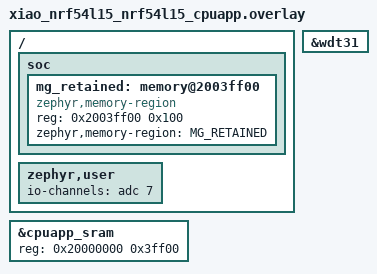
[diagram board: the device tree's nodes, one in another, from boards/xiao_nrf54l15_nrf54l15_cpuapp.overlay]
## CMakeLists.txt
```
# Copyright (c) Meta Platforms, Inc. and affiliates.
#
# Licensed under the Apache License, Version 2.0 (the "License");
# you may not use this file except in compliance with the License.
# You may obtain a copy of the License at
#
#     http://www.apache.org/licenses/LICENSE-2.0
#
# Unless required by applicable law or agreed to in writing, software
# distributed under the License is distributed on an "AS IS" BASIS,
# WITHOUT WARRANTIES OR CONDITIONS OF ANY KIND, either express or implied.
# See the License for the specific language governing permissions and
# limitations under the License.

cmake_minimum_required(VERSION 3.20.0)

# Before Zephyr's Kconfig runs: the version strings.
include(${CMAKE_CURRENT_SOURCE_DIR}/cmake/mg_version.cmake)

find_package(Zephyr REQUIRED HINTS $ENV{ZEPHYR_BASE})
project(muse_gadget_zephyr)

# The image id's build variant, guessed before Kconfig, against the effective
# configuration (cmake/mg_image_id.cmake): a mismatch fails the build.
mg_image_variant_check(${MG_IMAGE_VARIANT})

# The XIAO's flash map (mcuboot, slot0, slot1, storage) boots through MCUboot:
# without it the image would sit at slot0 with nothing at 0 to start it.
if(CONFIG_BOARD_XIAO_NRF54L15 AND NOT CONFIG_BOOTLOADER_MCUBOOT)
  message(FATAL_ERROR "Build the XIAO nRF54L15 with --sysbuild: it boots through MCUboot "
    "(sysbuild.conf). See AGENTS.md, Build.")
endif()

include(${CMAKE_CURRENT_SOURCE_DIR}/cmake/mg_common.cmake)

target_include_directories(app PRIVATE ${MG_PROTOCOLS} src)

target_sources(app PRIVATE
  src/main.c
  src/mg_core.c
  src/mg_clock.c
  src/mg_power.c
  src/mg_boot.c
  src/mg_health.c
  src/mg_settings.c
  src/mg_session.c
  src/mg_identity.c
  src/mg_json.c
  src/mg_psa.c
  src/mg_setup.c
  src/mg_setup_crypto.c
  src/mg_setup_store.c
  src/mg_token_proof.c
  src/mg_codec.c
  src/mg_audio.c
  src/mg_hpf.c
  src/mg_ble.c
  src/mg_connparam.c
  src/mg_throughput.c
  src/mg_led.c
  src/mg_led_pattern.c
  src/mg_button.c
)
# The TX path's ACL leg counts the controller's completed packets (mg_ble.c): the
# host's bt_conn_tx_notify(conn, false), once per Number of Completed Packets.
zephyr_link_libraries(-Wl,--wrap=bt_conn_tx_notify)
# A disconnect the host asks for on its own TX processor goes out from the
# system work queue (src/mg_bt_txfix.c: Zephyr v4.4.2's host would wait there
# for a command only that thread sends, then assert after 10 s).
if(CONFIG_BT_TX_PROCESSOR_THREAD AND CONFIG_BT_CONN)
  target_sources(app PRIVATE src/mg_bt_txfix.c)
  zephyr_link_libraries(-Wl,--wrap=bt_send -Wl,--wrap=bt_hci_disconnect)
endif()
target_sources_ifdef(CONFIG_MG_VM_SESSION app PRIVATE
  src/mg_envelope.c
  src/mg_vm_session.c
  src/mg_vm_link.c
  src/mg_vm_commands.c
  # Sealed credentials: the shared seal, vendored
  # unchanged, on this app's PSA Crypto.
  ../portable/mg_device_session/src/mg_session_seal.c
  src/mg_seal_crypto.c
)
if(CONFIG_MG_VM_SESSION)
  # After src: this app's own mg_token_proof.h comes first.
  target_include_directories(app PRIVATE
    ../portable/mg_device_session/include ../portable/mg_link_setup/include)
  # mgls_crypto.h's PSA types. MGSEAL_EXT_SHA stays 0 here: the seal's own
  # SHA-256 is smaller on this app than PSA's multipart hash, which nothing
  # else links (MGSEAL_EXT_SHA=1 measured +1,252 B of flash).
  target_compile_definitions(app PRIVATE MGLS_CRYPTO_PSA)
endif()
target_sources_ifdef(CONFIG_MG_AUDIO_QUEUE app PRIVATE src/mg_queue.c)
# A board's own app code (its board hooks, mg_app.h) lives beside the app in a
# directory with an app_ext.cmake; each one includes itself when its board
# builds.
file(GLOB mg_app_exts ${CMAKE_CURRENT_SOURCE_DIR}/*/app_ext.cmake)
foreach(ext ${mg_app_exts})
  include(${ext})
endforeach()
target_sources_ifdef(CONFIG_MG_BATTERY_ADC app PRIVATE src/mg_battery.c)
target_sources_ifdef(CONFIG_MG_SDK_TOKEN_SLOT app PRIVATE src/mg_token_slot.c)
if(CONFIG_MG_SDK_TOKEN_SLOT)
  # The updater finds the slot by its marker: exactly once in the image,
  # checked on zephyr.bin after every link.
  add_custom_target(mg_token_slot_check ALL
    COMMAND ${PYTHON_EXECUTABLE} ${CMAKE_CURRENT_SOURCE_DIR}/tools/check_token_slot.py
            ${ZEPHYR_BINARY_DIR}/${KERNEL_BIN_NAME}
    VERBATIM)
  add_dependencies(mg_token_slot_check zephyr_final)
endif()
if(NOT CONFIG_ARCH_POSIX)
  # Every Nordic UART word is classified and gated (tools/check_nus_words.py):
  # before the app compiles, so an unclassified word never builds.
  add_custom_target(mg_nus_words_check ALL
    COMMAND ${PYTHON_EXECUTABLE} ${CMAKE_CURRENT_SOURCE_DIR}/tools/check_nus_words.py
            ${CMAKE_CURRENT_SOURCE_DIR}/src/mg_nus.c ${CMAKE_CURRENT_SOURCE_DIR}/src/mg_nus_policy.h
    VERBATIM)
  add_dependencies(app mg_nus_words_check)
  # Every owner-content wireless read is listed and gated
  # (tools/check_owner_reads.py, src/mg_owner_reads.h).
  add_custom_target(mg_owner_reads_check ALL
    COMMAND ${PYTHON_EXECUTABLE} ${CMAKE_CURRENT_SOURCE_DIR}/tools/check_owner_reads.py
            ${CMAKE_CURRENT_SOURCE_DIR}/src
    VERBATIM)
  add_dependencies(app mg_owner_reads_check)
  # No log line formats a secret or a hex buffer (every line can reach the
  # Nordic UART mirror; tools/check_log_secrets.py), board code included:
  # every directory beside src/ with an app_ext.cmake.
  set(mg_app_ext_dirs)
  file(GLOB mg_app_ext_files ${CMAKE_CURRENT_SOURCE_DIR}/*/app_ext.cmake)
  foreach(mg_ext ${mg_app_ext_files})
    get_filename_component(mg_ext_dir ${mg_ext} DIRECTORY)
    list(APPEND mg_app_ext_dirs ${mg_ext_dir})
  endforeach()
  add_custom_target(mg_log_secrets_check ALL
    COMMAND ${PYTHON_EXECUTABLE} ${CMAKE_CURRENT_SOURCE_DIR}/tools/check_log_secrets.py
            ${CMAKE_CURRENT_SOURCE_DIR}/src ${mg_app_ext_dirs}
    VERBATIM)
  add_dependencies(app mg_log_secrets_check)
  # The malloc arena (all RAM no static data uses) holds both the device
  # session's block and SMP's, the BLE recovery tier: a build whose statics
  # leave too little fails here instead of an update failing in the field
  # (tools/check_arena.py).
  if(CONFIG_COMMON_LIBC_MALLOC_ARENA_SIZE EQUAL -1 AND CONFIG_MCUMGR)
    math(EXPR mg_ram_end "${CONFIG_SRAM_BASE_ADDRESS} + ${CONFIG_SRAM_SIZE} * 1024" OUTPUT_FORMAT HEXADECIMAL)
    add_custom_target(mg_arena_check ALL
      COMMAND ${PYTHON_EXECUTABLE} ${CMAKE_CURRENT_SOURCE_DIR}/tools/check_arena.py
              --nm ${CMAKE_NM} --elf ${ZEPHYR_BINARY_DIR}/${KERNEL_ELF_NAME}
              --ram-end ${mg_ram_end} --min-kb 48
      VERBATIM)
    add_dependencies(mg_arena_check zephyr_final)
  endif()
  # The mic's token-proof gate is linked, and a release image has no bench
  # path around it (tools/check_mic_gate.py): checked after every link. A
  # bench-mode image passes its own build's check (--bench-mode); what
  # refuses it as a release is its .bench marker and a separate
  # check_mic_gate.py --release run without --bench-mode (publish tooling).
  if(CONFIG_MG_AUTOMATION)
    set(mg_mic_release "")
  elseif(CONFIG_MG_BENCH_MODE)
    set(mg_mic_release --release --bench-mode)
  else()
    set(mg_mic_release "--release")
  endif()
  add_custom_target(mg_mic_gate_check ALL
    COMMAND ${PYTHON_EXECUTABLE} ${CMAKE_CURRENT_SOURCE_DIR}/tools/check_mic_gate.py
            --nm ${CMAKE_NM} --elf ${ZEPHYR_BINARY_DIR}/${KERNEL_ELF_NAME}
            --bin ${ZEPHYR_BINARY_DIR}/${KERNEL_BIN_NAME} ${mg_mic_release}
    VERBATIM)
  add_dependencies(mg_mic_gate_check zephyr_final)
endif()
target_sources_ifdef(CONFIG_MG_NUS app PRIVATE src/mg_nus.c)
if(CONFIG_MCUMGR_TRANSPORT_BT AND NOT CONFIG_MG_DFU AND NOT CONFIG_MG_SMP_GATE_BOARD)
  # mg_ota.c (or mg_smp_gate.c) holds the update writes' token-proof gate:
  # without one SMP over Bluetooth would take updates from anyone.
  message(FATAL_ERROR "CONFIG_MCUMGR_TRANSPORT_BT needs CONFIG_MG_DFU (the update gate) or "
                      "CONFIG_MG_SMP_GATE_BOARD; turn it off for a build without Bluetooth updates")
endif()
if(CONFIG_MG_SMP_GATE_BOARD)
  # Each request's source connection (src/mg_smp_req_gen.c): its first
  # fragment's, stamped where the transport hands the request over, read
  # while its handlers run; with reassembly a partly received request whose
  # connection is gone is dropped before the next write is collected.
  target_sources(app PRIVATE src/mg_smp_gate.c src/mg_smp_req_gen.c)
  zephyr_link_libraries(-Wl,--wrap=smp_rx_req -Wl,--wrap=smp_process_request_packet)
  if(CONFIG_MCUMGR_TRANSPORT_REASSEMBLY)
    target_include_directories(app PRIVATE ${ZEPHYR_BASE}/subsys/mgmt/mcumgr/transport/include)
    zephyr_link_libraries(-Wl,--wrap=smp_reassembly_expected -Wl,--wrap=smp_reassembly_collect)
  endif()
endif()
target_sources_ifdef(CONFIG_MG_DFU app PRIVATE src/mg_ota.c)
if(CONFIG_MG_DFU)
  # img_mgmt's image state write changes the next boot only through
  # boot_set_next(): mg_ota.c applies a client's confirm that comes before
  # the boot is healthy at the healthy mark (src/mg_ota_policy.h).
  target_link_libraries(app PRIVATE MCUBOOT_BOOTUTIL)
  zephyr_link_libraries(-Wl,--wrap=boot_set_next)
  # Update support takes no base memory (src/mg_smp_mem.c): MCUmgr's
  # buffers and work queue from src/zephyr/smp.c, the copy of Zephyr's built
  # in its place, and the image writer's context from the wrap of
  # img_mgmt_write_image_data(), all allocated only while SMP is in use.
  target_sources(app PRIVATE src/mg_smp_mem.c)
  zephyr_link_libraries(-Wl,--wrap=img_mgmt_write_image_data)
  if(CONFIG_MG_QUEUE_IN_SLOT1)
    # An image erase takes slot1 from the clips only once img_mgmt accepted it.
    zephyr_link_libraries(-Wl,--wrap=img_mgmt_erase_slot)
  endif()
  get_target_property(mg_mcumgr_srcs mcumgr_transport SOURCES)
  list(FILTER mg_mcumgr_srcs EXCLUDE REGEX "(^|/subsys/mgmt/mcumgr/transport/)src/smp\\.c$")
  set_property(TARGET mcumgr_transport PROPERTY SOURCES ${mg_mcumgr_srcs})
  target_sources(mcumgr_transport PRIVATE ${CMAKE_CURRENT_SOURCE_DIR}/src/zephyr/smp.c)
  if(CONFIG_MCUMGR_TRANSPORT_REASSEMBLY)
    # smp_bt asks smp_reassembly_expected() before it collects each SMP
    # write: mg_ota.c drops a partly received request there after a gap (a
    # lost write) or when the link it began on is gone, and records the
    # connection of a request's first fragment.
    target_include_directories(app PRIVATE ${ZEPHYR_BASE}/subsys/mgmt/mcumgr/transport/include)
    zephyr_link_libraries(-Wl,--wrap=smp_reassembly_expected -Wl,--wrap=smp_reassembly_collect)
  endif()
endif()
target_sources_ifdef(CONFIG_MG_POWER_OFF app PRIVATE src/mg_poweroff.c src/mg_usb.c)
target_sources_ifdef(CONFIG_MG_BENCH app PRIVATE src/mg_bench.c)
target_sources_ifdef(CONFIG_MG_AUDIO_SRC_DMIC app PRIVATE src/mg_audio_dmic.c)
target_sources_ifdef(CONFIG_MG_LC3_24K app PRIVATE src/mg_resample.c)
target_sources_ifdef(CONFIG_MG_AUDIO_SRC_SYNTH app PRIVATE src/mg_audio_synth.c)
if(CONFIG_MG_BSIM_TESTS)
  add_subdirectory(${ZEPHYR_BASE}/tests/bsim/babblekit babblekit)
  target_link_libraries(app PRIVATE babblekit)
  target_sources(app PRIVATE tests/bsim/gadget_hooks.c)
  zephyr_include_directories(
    $ENV{BSIM_COMPONENTS_PATH}/libUtilv1/src $ENV{BSIM_COMPONENTS_PATH}/libPhyComv1/src)
endif()

mg_add_transcript(app)
mg_add_sbc(app)
if(CONFIG_MG_LC3)
  mg_add_lc3(app)
endif()
```

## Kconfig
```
# Copyright (c) Meta Platforms, Inc. and affiliates.
#
# Licensed under the Apache License, Version 2.0 (the "License");
# you may not use this file except in compliance with the License.
# You may obtain a copy of the License at
#
#     http://www.apache.org/licenses/LICENSE-2.0
#
# Unless required by applicable law or agreed to in writing, software
# distributed under the License is distributed on an "AS IS" BASIS,
# WITHOUT WARRANTIES OR CONDITIONS OF ANY KIND, either express or implied.
# See the License for the specific language governing permissions and
# limitations under the License.

mainmenu "Muse Gadget (Zephyr)"

rsource "Kconfig.mg"
# A board's own app code, in a directory beside the app (its app_ext.cmake,
# CMakeLists.txt), may bring its own options in a Kconfig.ext.
orsource "*/Kconfig.ext"

# The controller's side of the link this app asks for (prj.conf): defaults
# here, not assignments, so they apply only where the controller is built
# into this image.
config BT_CTLR_DATA_LENGTH_MAX
	default 251

config BT_CTLR_PHY_2M
	default y

# Device Information Service strings (mgcommands.h). The firmware revision
# is the version cmake/mg_version.cmake works out from VERSION and git;
# the MCUboot image version comes from the same place.
config BT_DIS_FW_REV_STR
	default "$(MG_FW_VERSION)"

if BOOTLOADER_MCUBOOT
config MCUBOOT_IMGTOOL_SIGN_VERSION
	default "$(MG_IMAGE_VERSION)"
endif

config BT_DIS_MANUF_NAME_STR
	default "Seeed Studio"

config BT_DIS_MODEL_NUMBER_STR
	default "XIAO nRF54L15"

config BT_DIS_SW_REV_STR
	default "mg1"

# The connection parameters GAP advertises (Peripheral Preferred Connection
# Parameters) are the ones mg_connparam.c asks for.
config BT_PERIPHERAL_PREF_MIN_INT
	default MG_CONN_INTERVAL_MIN

config BT_PERIPHERAL_PREF_MAX_INT
	default MG_CONN_INTERVAL_MAX

config BT_PERIPHERAL_PREF_LATENCY
	default MG_CONN_LATENCY

config BT_PERIPHERAL_PREF_TIMEOUT
	default MG_CONN_TIMEOUT

source "Kconfig.zephyr"
```

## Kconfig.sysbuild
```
# Copyright (c) Meta Platforms, Inc. and affiliates.
#
# Licensed under the Apache License, Version 2.0 (the "License");
# you may not use this file except in compliance with the License.
# You may obtain a copy of the License at
#
#     http://www.apache.org/licenses/LICENSE-2.0
#
# Unless required by applicable law or agreed to in writing, software
# distributed under the License is distributed on an "AS IS" BASIS,
# WITHOUT WARRANTIES OR CONDITIONS OF ANY KIND, either express or implied.
# See the License for the specific language governing permissions and
# limitations under the License.

# MCUboot's development keys (bootloader/mcuboot/root-*.pem)
# are public, so anyone can sign images a unit built with one accepts. A build
# signed with one fails at configure time unless it says it's for development
# (sysbuild-dev.conf); production sets SB_CONFIG_BOOT_SIGNATURE_KEY_FILE to its
# own private key, kept out of the repository (sysbuild.cmake,
# tools/check_signing_key.py).
config MG_DEV_SIGNING_KEY
	bool "Development build: sign with MCUboot's public development key"
	help
	  Allows SB_CONFIG_BOOT_SIGNATURE_KEY_FILE to be one of MCUboot's public
	  development keys (the default). Units built with it accept any image
	  signed with that key, which anyone can do: for benches and development
	  units only, never for units in users' hands.

# A board with a separate network core names its board (NET_CORE_BOARD, in
# the board's own Kconfig.sysbuild); the Bluetooth controller (Zephyr's
# hci_ipc sample) is then built for it beside the application.
config NET_CORE_BOARD
	string

config NET_CORE_IMAGE_HCI_IPC
	bool "Bluetooth controller image (hci_ipc) on the network core"
	default y
	depends on NET_CORE_BOARD != ""

source "share/sysbuild/Kconfig"
```

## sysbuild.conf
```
# Copyright (c) Meta Platforms, Inc. and affiliates.
#
# Licensed under the Apache License, Version 2.0 (the "License");
# you may not use this file except in compliance with the License.
# You may obtain a copy of the License at
#
#     http://www.apache.org/licenses/LICENSE-2.0
#
# Unless required by applicable law or agreed to in writing, software
# distributed under the License is distributed on an "AS IS" BASIS,
# WITHOUT WARRANTIES OR CONDITIONS OF ANY KIND, either express or implied.
# See the License for the specific language governing permissions and
# limitations under the License.


# The XIAO nRF54L15 boots through MCUboot (build with --sysbuild). Swap using
# move keeps test, confirm and revert: a new image runs on test, the app
# confirms it once BLE is up, and an image that never gets there is swapped
# back at the next reset. Images are signed with ECDSA P-256. Production
# builds set SB_CONFIG_BOOT_SIGNATURE_KEY_FILE to their own private key (kept
# out of the repository); MCUboot's development key
# (bootloader/mcuboot/root-ec-p256.pem, the default) is public, so a build
# with it fails unless it adds sysbuild-dev.conf (a bench or development
# unit; sysbuild.cmake).
SB_CONFIG_BOOTLOADER_MCUBOOT=y
SB_CONFIG_MCUBOOT_MODE_SWAP_USING_MOVE=y
SB_CONFIG_BOOT_SIGNATURE_TYPE_ECDSA_P256=y
```

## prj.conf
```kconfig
# Copyright (c) Meta Platforms, Inc. and affiliates.
#
# Licensed under the Apache License, Version 2.0 (the "License");
# you may not use this file except in compliance with the License.
# You may obtain a copy of the License at
#
#     http://www.apache.org/licenses/LICENSE-2.0
#
# Unless required by applicable law or agreed to in writing, software
# distributed under the License is distributed on an "AS IS" BASIS,
# WITHOUT WARRANTIES OR CONDITIONS OF ANY KIND, either express or implied.
# See the License for the specific language governing permissions and
# limitations under the License.

# Bluetooth: one peripheral connection, large MTU and data length for audio.
CONFIG_BT=y
CONFIG_BT_PERIPHERAL=y
CONFIG_BT_MAX_CONN=1
CONFIG_BT_GATT_CLIENT=y
CONFIG_BT_DEVICE_NAME="MuseGadget"
CONFIG_BT_DEVICE_NAME_DYNAMIC=y
CONFIG_BT_DEVICE_NAME_MAX=32
CONFIG_BT_DEVICE_APPEARANCE=0
CONFIG_BT_L2CAP_TX_MTU=247
CONFIG_BT_BUF_ACL_RX_SIZE=251
CONFIG_BT_BUF_ACL_TX_SIZE=251
CONFIG_BT_BUF_ACL_TX_COUNT=12
# Phone->device receive buffers stay at Zephyr's defaults (one controller RX
# PDU buffer, no extra ACL buffers): 8 and 7 more cost 3,776 B of static RAM
# and bought nothing measurable. A XIAO from a Mac, alternating
# images: an SMP upload 16.3-17.8 KB/s with 8/7 against 16.4-16.9 with the
# defaults, Link setup 3.3-5.0 s against 3.1-4.4 s, the throughput test's
# receive side 33-47 KB/s against 34-51 KB/s with nothing lost (the Mac's
# writes are the limit); BabbleSim receives 163 KB/s either way. A short
# controller pool doesn't lose writes: the link layer NACKs and the central
# retransmits.
CONFIG_BT_BUF_EVT_RX_COUNT=16
# Every board this app builds for asks for 251-byte link-layer PDUs and the
# 2M PHY right after connecting (mg_ble.c) and logs what it gets; the
# controller's side (CONFIG_BT_CTLR_DATA_LENGTH_MAX 251, CONFIG_BT_CTLR_PHY_2M)
# is a default in Kconfig, so a board whose controller runs on another core
# (an nRF5340's network core) doesn't assign symbols it doesn't have.
CONFIG_BT_USER_DATA_LEN_UPDATE=y
CONFIG_BT_USER_PHY_UPDATE=y
# mg_connparam.c asks for the connection parameters itself (15 ms, latency
# 10, 4 s; latency off while the phone streams to the gadget), so the host
# doesn't send its own update. CONFIG_MG_CONN_* sets them, and the GAP
# preferred parameters follow (Kconfig).
CONFIG_BT_GAP_AUTO_UPDATE_CONN_PARAMS=n
# The host holds a peripheral's parameter requests back this long after
# connecting (the Core spec's TGAP(conn_pause_peripheral) is 1 s; Zephyr's
# default is 5 s, past most of a phone's setup traffic).
CONFIG_BT_CONN_PARAM_UPDATE_TIMEOUT=1000
CONFIG_BT_RX_STACK_SIZE=2560

# No BLE bonding: the device session's credentials go only sealed under the
# token proof, which needs no encrypted link; a bond opens nothing (every
# unsealed hello is answered insecure).
CONFIG_BT_SMP=n

# Standard services.
CONFIG_BT_BAS=y
CONFIG_BT_DIS=y
CONFIG_BT_DIS_PNP=n
CONFIG_BT_DIS_MODEL_NUMBER=y
CONFIG_BT_DIS_MANUF_NAME=y
CONFIG_BT_DIS_FW_REV=y
CONFIG_BT_DIS_SW_REV=y

# Settings (push-to-talk, codec, haptics, queue) in ZMS.
CONFIG_FLASH=y
CONFIG_FLASH_MAP=y
CONFIG_ZMS=y
CONFIG_SETTINGS=y
CONFIG_SETTINGS_ZMS=y
# PSA key slots: Link setup holds at most two keys at a time.
CONFIG_MBEDTLS_PSA_KEY_SLOT_COUNT=4

# Offline clip checksums.
CONFIG_CRC=y

# Button through the input subsystem (gpio-keys debounces).
CONFIG_INPUT=y
CONFIG_GPIO=y

CONFIG_LOG=y
CONFIG_MAIN_STACK_SIZE=2048
CONFIG_SYSTEM_WORKQUEUE_STACK_SIZE=2048

# The bench console (CONFIG_MG_BENCH, every build) reads the console UART a
# character at a time.
CONFIG_CONSOLE_SUBSYS=y
CONFIG_CONSOLE_GETCHAR=y
```

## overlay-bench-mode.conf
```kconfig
# Copyright (c) Meta Platforms, Inc. and affiliates.
#
# Licensed under the Apache License, Version 2.0 (the "License");
# you may not use this file except in compliance with the License.
# You may obtain a copy of the License at
#
#     http://www.apache.org/licenses/LICENSE-2.0
#
# Unless required by applicable law or agreed to in writing, software
# distributed under the License is distributed on an "AS IS" BASIS,
# WITHOUT WARRANTIES OR CONDITIONS OF ANY KIND, either express or implied.
# See the License for the specific language governing permissions and
# limitations under the License.

# Bench mode alone: add to any build, overlay-release.conf included,
# to run that build's gates end to end with no human. The image id marks it
# (.bench) and tools/check_mic_gate.py --release refuses it: it never ships.
#   -DEXTRA_CONF_FILE="overlay-release.conf;overlay-bench-mode.conf"
CONFIG_MG_BENCH_MODE=y
```

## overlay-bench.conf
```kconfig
# Copyright (c) Meta Platforms, Inc. and affiliates.
#
# Licensed under the Apache License, Version 2.0 (the "License");
# you may not use this file except in compliance with the License.
# You may obtain a copy of the License at
#
#     http://www.apache.org/licenses/LICENSE-2.0
#
# Unless required by applicable law or agreed to in writing, software
# distributed under the License is distributed on an "AS IS" BASIS,
# WITHOUT WARRANTIES OR CONDITIONS OF ANY KIND, either express or implied.
# See the License for the specific language governing permissions and
# limitations under the License.


# Lab and CI builds: the automation tools (CONFIG_MG_AUTOMATION, off in
# release builds); the bench console is in every build.
# -DEXTRA_CONF_FILE=overlay-bench.conf.
CONFIG_MG_AUTOMATION=y
CONFIG_MG_BENCH=y
CONFIG_CONSOLE_GETCHAR=y
# Bench builds offer gadget- at a new setup (off by default:
# CONFIG_MG_NODE_ID_GADGET).
CONFIG_MG_NODE_ID_GADGET=y
# Bench mode: every human step scriptable; the image id marks it
# (cmake/mg_image_id.cmake) and it never ships.
CONFIG_MG_BENCH_MODE=y
```

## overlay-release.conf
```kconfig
# Copyright (c) Meta Platforms, Inc. and affiliates.
#
# Licensed under the Apache License, Version 2.0 (the "License");
# you may not use this file except in compliance with the License.
# You may obtain a copy of the License at
#
#     http://www.apache.org/licenses/LICENSE-2.0
#
# Unless required by applicable law or agreed to in writing, software
# distributed under the License is distributed on an "AS IS" BASIS,
# WITHOUT WARRANTIES OR CONDITIONS OF ANY KIND, either express or implied.
# See the License for the specific language governing permissions and
# limitations under the License.

# A release build: what leaves the bench (a page, a published image, a
# user's unit). The automation tools are off (CONFIG_MG_AUTOMATION, the
# default here; this file says so for a board or conf that turns it on), so
# the Nordic UART's state-changing words need the token proof, the bench
# switch takes the proof only and refuses a set-up gadget, the recovery
# bench rows are refused, setup confirms only on the real button, start_mic
# needs a press, and an unproven central's Bluetooth update write is
# answered 10 with the update prompt (one press, bound to the upload). Bench
# mode is off too: overlay-bench-mode.conf after it turns it back on, and
# that image is marked .bench. check_mic_gate.py --release runs after the
# link. Its image id and firmware string carry no .auto or .bench
# (cmake/mg_image_id.cmake). Pass it last: a conf file after it, or
# -DCONFIG_MG_AUTOMATION=y, turns automation back on (the last value wins):
#   -DEXTRA_CONF_FILE="<the token conf>;overlay-release.conf"
CONFIG_MG_AUTOMATION=n
CONFIG_MG_BENCH_MODE=n
```

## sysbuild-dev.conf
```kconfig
# Copyright (c) Meta Platforms, Inc. and affiliates.
#
# Licensed under the Apache License, Version 2.0 (the "License");
# you may not use this file except in compliance with the License.
# You may obtain a copy of the License at
#
#     http://www.apache.org/licenses/LICENSE-2.0
#
# Unless required by applicable law or agreed to in writing, software
# distributed under the License is distributed on an "AS IS" BASIS,
# WITHOUT WARRANTIES OR CONDITIONS OF ANY KIND, either express or implied.
# See the License for the specific language governing permissions and
# limitations under the License.

# A development build: sign with MCUboot's public
# development key, which anyone can sign for. Bench and development units
# only. Pass it with -DSB_EXTRA_CONF_FILE=sysbuild-dev.conf; production builds
# set SB_CONFIG_BOOT_SIGNATURE_KEY_FILE to their own private key instead.
SB_CONFIG_MG_DEV_SIGNING_KEY=y
```

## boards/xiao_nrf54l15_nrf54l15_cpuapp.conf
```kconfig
# Copyright (c) Meta Platforms, Inc. and affiliates.
#
# Licensed under the Apache License, Version 2.0 (the "License");
# you may not use this file except in compliance with the License.
# You may obtain a copy of the License at
#
#     http://www.apache.org/licenses/LICENSE-2.0
#
# Unless required by applicable law or agreed to in writing, software
# distributed under the License is distributed on an "AS IS" BASIS,
# WITHOUT WARRANTIES OR CONDITIONS OF ANY KIND, either express or implied.
# See the License for the specific language governing permissions and
# limitations under the License.


# Muse Gadget catalog model code: the XIAO advertises
# MuseGadget-XN54-XXXXXX, XXXXXX the last three bytes of its Bluetooth
# address (22 of the 25 characters the scan response leaves for the name).
CONFIG_MG_DEVICE_PRODUCT_CODE="XN54"

CONFIG_FPU=y

# Recovery and diagnostics: the reset reason for the boot log
# and the NUS console; the watchdog (WDT31, enabled in the overlay) comes
# with CONFIG_MG_WATCHDOG.
CONFIG_HWINFO=y

# Firmware updates over BLE: MCUmgr SMP (image and OS groups) beside the mg
# service, with MCUboot from sysbuild (sysbuild.conf). The image lives in
# slot0; MG_DFU confirms test images and shares slot1 with the clip queue.
CONFIG_MCUMGR=y
CONFIG_NET_BUF=y
CONFIG_ZCBOR=y
CONFIG_CRC=y
CONFIG_FLASH=y
CONFIG_FLASH_MAP=y
CONFIG_STREAM_FLASH=y
CONFIG_IMG_MANAGER=y
CONFIG_MCUBOOT_IMG_MANAGER=y
CONFIG_MCUMGR_GRP_IMG=y
CONFIG_MCUMGR_GRP_IMG_STATUS_HOOKS=y
CONFIG_MCUMGR_GRP_OS=y
CONFIG_MCUMGR_GRP_OS_ECHO=y
CONFIG_MCUMGR_GRP_OS_INFO=y
CONFIG_MCUMGR_MGMT_NOTIFICATION_HOOKS=y
CONFIG_MCUMGR_TRANSPORT_BT=y
# One SMP request spans several ATT writes (reassembly) into a 512-byte
# buffer, which clients learn from the OS group's MCUmgr parameters
# (buf_size, buf_count) and fill. 512 at most: the Android app sizes
# each request to
# buf_size and writes MTU - 3 bytes at a time, and Android refuses any
# write over 512 bytes, so more fails at once on a phone at MTU 517. It
# also holds the largest response (image state, two slots: 258 bytes).
# Four buffers: Android keeps three requests in flight and Zephyr counts
# the response's buffer too. The image is written in 4 KB blocks,
# so the radio-synchronised flash driver
# (CONFIG_SOC_FLASH_NRF_RADIO_SYNC_TICKER) waits for a gap in the radio
# schedule once per 4 KB, not per request.
CONFIG_MCUMGR_TRANSPORT_BT_REASSEMBLY=y
CONFIG_MCUMGR_TRANSPORT_NETBUF_SIZE=512
CONFIG_MCUMGR_TRANSPORT_NETBUF_COUNT=4
CONFIG_MCUMGR_GRP_OS_MCUMGR_PARAMS=y
# The SMP reset: the answer, the gadget drops the link itself at 100 ms
# (CONFIG_MG_DFU_RESET_DISCONNECT_MS), and restarts at 500 ms.
CONFIG_MCUMGR_GRP_OS_RESET_MS=500
CONFIG_IMG_BLOCK_BUF_SIZE=4096
# No erase of the whole image's size at an upload's first chunk: RRAM needs
# none, and img_mgmt's upfront flatten of a 320 KB image took about 38 s
# through the radio-synchronised driver before the first chunk was answered
# (measured on a XIAO from a Mac): longer than the Android app's
# 4 x 5 s for that chunk ("Upload stalled") and iOS's 30 s. Progressively,
# flash_img only blanks MCUboot's trailer (a few KB) before the first write.
CONFIG_IMG_ERASE_PROGRESSIVELY=y
CONFIG_MCUMGR_TRANSPORT_WORKQUEUE_STACK_SIZE=4096

# The boot record sits in the overlay's mg_retained block at the top
# of SRAM; the XIAO's MCUboot (swap using move) reaches about 0x200043e0
# (_image_ram_end), so this leaves room for its growth and the build checks
# the block stays above it.
CONFIG_MG_BOOT_RAM_END=0x20008000
```

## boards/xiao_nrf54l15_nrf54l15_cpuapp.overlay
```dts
/*
 * Copyright (c) Meta Platforms, Inc. and affiliates.
 *
 * Licensed under the Apache License, Version 2.0 (the "License");
 * you may not use this file except in compliance with the License.
 * You may obtain a copy of the License at
 *
 *     http://www.apache.org/licenses/LICENSE-2.0
 *
 * Unless required by applicable law or agreed to in writing, software
 * distributed under the License is distributed on an "AS IS" BASIS,
 * WITHOUT WARRANTIES OR CONDITIONS OF ANY KIND, either express or implied.
 * See the License for the specific language governing permissions and
 * limitations under the License.
 */

/*
 * Seeed XIAO nRF54L15 (Sense). The Sense's PDM microphone is on pdm20
 * (dmic_dev in the board file), the user button is sw0 and the LED led0.
 *
 * The RRAM keeps the board's standard MCUboot map (nrf54l15_cpuapp_partition.dtsi):
 * mcuboot 62 KB at 0, slot0 712 KB at 0x10000, slot1 712 KB at 0xc2000 and
 * storage (settings) 36 KB at 0x174000. slot1 doubles as the offline clip
 * queue while no firmware update needs it (src/mg_queue.h).
 */

/* The boot record's retained block (src/mg_health.c): the top 256 B
 * of SRAM, outside the app's RAM; the XIAO's MCUboot (swap using move) uses
 * RAM only up to about 0x200043e0 (CONFIG_MG_BOOT_RAM_END in the board's
 * .conf). */
&cpuapp_sram {
	reg = <0x20000000 0x3ff00>;
	ranges = <0x0 0x20000000 0x3ff00>;
};

/ {
	soc {
		mg_retained: memory@2003ff00 {
			compatible = "zephyr,memory-region", "mmio-sram";
			reg = <0x2003ff00 0x100>;
			zephyr,memory-region = "MG_RETAINED";
		};
	};
};

/* The watchdog (CONFIG_MG_WATCHDOG); the board's watchdog0 alias. */
&wdt31 {
	status = "okay";
};

/ {
	zephyr,user {
		/* VBAT through the board's 2:1 divider, switched on by P1.15 (vbat_pwr,
		 * on from boot), on AIN7: channel 7 of the board's ADC node. */
		io-channels = <&adc 7>;
		/* No mg-usb-sense-gpios: nothing on this board tells the nRF54L15
		 * that USB power is there (src/mg_usb.c has the measurements). */
	};
};
```

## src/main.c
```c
/*
 * Copyright (c) Meta Platforms, Inc. and affiliates.
 *
 * Licensed under the Apache License, Version 2.0 (the "License");
 * you may not use this file except in compliance with the License.
 * You may obtain a copy of the License at
 *
 *     http://www.apache.org/licenses/LICENSE-2.0
 *
 * Unless required by applicable law or agreed to in writing, software
 * distributed under the License is distributed on an "AS IS" BASIS,
 * WITHOUT WARRANTIES OR CONDITIONS OF ANY KIND, either express or implied.
 * See the License for the specific language governing permissions and
 * limitations under the License.
 */

#include <errno.h>
#include <string.h>

#include <zephyr/kernel.h>
#include <zephyr/logging/log.h>
#include <zephyr/settings/settings.h>

#include "mg_app.h"
#include "mg_audio.h"
#include "mg_button.h"
#include "mg_clock.h"
#include "mg_boot.h"
#include "mg_core.h"
#include "mg_health.h"
#include "mg_led.h"
#include "mg_reset_hold.h"
#include "mg_power.h"
#if defined(CONFIG_MG_POWER_OFF)
#include "mg_usb.h"
#endif
#if defined(CONFIG_MG_DFU)
#include "mg_ota.h"
#endif
#include "mg_session.h"
#include "mg_settings.h"
#include "mg_resetup_policy.h"
#include "mg_setup.h"
#include "mg_setup_store.h"
#include "mg_transport.h"
#if defined(CONFIG_MG_VM_SESSION)
#include "mg_vm_link.h"
#include "mg_vm_session.h"
#endif
#if defined(CONFIG_MG_AUDIO_QUEUE)
#include "mg_queue.h"
#endif
#if defined(CONFIG_MG_BATTERY_ADC)
#include "mg_battery.h"
#endif

LOG_MODULE_REGISTER(mg_main, CONFIG_MG_LOG_LEVEL);

/* Link setup runs P-256 ECDH (mbedTLS) on this queue. */
K_THREAD_STACK_DEFINE(app_stack, 6144);
static struct k_work_q app_wq;

struct k_work_q *mg_app_wq(void)
{
	return &app_wq;
}

const char *mg_app_version(void)
{
	return CONFIG_BT_DIS_FW_REV_STR;
}

static struct k_work_delayable battery_work;

uint8_t mg_app_battery_percent(void)
{
	return mg_power_battery()->percent;
}

int mg_app_battery_mv(void)
{
	const struct mg_battery_state *b = mg_power_battery();

	return b->measured ? b->mv : -ENODEV;
}

int mg_app_usb_present(void)
{
#if defined(CONFIG_MG_POWER_OFF)
	return mg_usb_present();
#else
	return -ENOTSUP;
#endif
}

/* Battery Level, report_battery_status and the low-battery rules all come
 * from mg_power.c, fed here. */
static void battery_fn(struct k_work *w)
{
	const struct mg_battery_state *b = mg_power_battery();

	ARG_UNUSED(w);
#if defined(CONFIG_MG_BATTERY_ADC)
	uint32_t ev = mg_power_reading(mg_battery_read_mv(), k_uptime_get_32());

	LOG_DBG("battery %d mV, %u%%", b->mv, b->percent);
	/* Low battery: warn at 15 %, flash at 10 %, power off cleanly at
	 * CONFIG_MG_BATTERY_SHUTDOWN_MV, all only with a cell. */
	if (ev & MG_POWER_EV_LOW) {
		LOG_WRN("battery low: %d mV, %u%%", b->mv, b->percent);
	}
#if defined(CONFIG_MG_BATTERY_STATUS)
	if (ev & MG_POWER_EV_REPORT) {
		/* Unsolicited report_battery_status. */
		LOG_INF("battery %s, %u%%: report_battery_status sent",
			b->present ? "present" : "gone", b->percent);
		mg_core_battery_report();
	}
#endif
	if (ev & MG_POWER_EV_CRITICAL) {
		LOG_WRN("battery critical: %d mV, %u%%; the LED flashes every 30 s", b->mv,
			b->percent);
		mg_led_set(MG_LED_LOW_BATTERY, true);
	}
	if (ev & MG_POWER_EV_RECOVERED) {
		LOG_INF("battery fine again: %d mV, %u%%", b->mv, b->percent);
		mg_led_set(MG_LED_LOW_BATTERY, false);
	}
	if (ev & MG_POWER_EV_SHUTDOWN) {
		LOG_ERR("battery empty: %d mV <= %d mV; powering off before a brownout", b->mv,
			CONFIG_MG_BATTERY_SHUTDOWN_MV);
#if defined(CONFIG_MG_POWER_OFF)
		mg_app_power_off("battery empty");
		/* Polled on: if powering off fails the battery is still watched
		 * (a pending power off isn't asked twice). */
		k_work_reschedule(&battery_work, K_SECONDS(10));
		return;
#endif
	}
#endif
	mg_ble_set_battery(b->percent);
	k_work_reschedule(&battery_work, K_SECONDS(b->critical ? 10 : 60));
}

/* A board's extra conditions for the setup reset gesture (e.g. only with
 * the charger present); none by default. */
__weak bool mg_board_reset_hold_allowed(void)
{
	return true;
}

/* Whether the hold passes a SAFE point first (recovery tier 3 by button:
 * every gadget has a button route into SAFE): CONFIG_MG_SAFE_HOLD; a board
 * can narrow it (e.g. only with the charger present). */
__weak bool mg_board_safe_hold_allowed(void)
{
	return IS_ENABLED(CONFIG_MG_SAFE_HOLD);
}

enum boot_hold {
	BOOT_HOLD_NONE,
	BOOT_HOLD_SETUP, /* released before the SAFE cue: setup mode */
	BOOT_HOLD_SAFE,
	BOOT_HOLD_RESET,
};

/* The boot hold (src/mg_reset_hold.h): on a cold boot with the key
 * down, held CONFIG_MG_RESET_HOLD_MS then released (after the LED's
 * "release now" cue) within CONFIG_MG_RESET_RELEASE_MS resets the setup;
 * where the board allows it, a release after the SAFE cue
 * (CONFIG_MG_SAFE_HOLD_MS) and before that boots once in SAFE mode. */
static enum boot_hold held_for_reset(void)
{
	uint32_t cause = mg_health_reset_cause();
	struct mg_rh h = {0};
	bool reset_ok, safe_ok;

	if (!mg_reset_hold_cold(cause)) {
		LOG_INF("button down at boot, but not a cold boot (reset cause 0x%x: a wake "
			"from power off, an update, a watchdog): not a reset gesture",
			cause);
		return BOOT_HOLD_NONE;
	}
	reset_ok = mg_board_reset_hold_allowed();
	safe_ok = mg_board_safe_hold_allowed();
	if (!reset_ok && !safe_ok) {
		LOG_INF("button held at power-up: the board doesn't allow a reset now");
		return BOOT_HOLD_NONE;
	}
	if (safe_ok) {
		LOG_INF("button held at power-up: release after %d s for SAFE mode, after %d s "
			"to reset setup",
			CONFIG_MG_SAFE_HOLD_MS / 1000, CONFIG_MG_RESET_HOLD_MS / 1000);
	} else {
		LOG_INF("button held at power-up: hold %d s, then release, to reset setup",
			CONFIG_MG_RESET_HOLD_MS / 1000);
	}
	/* Times from the uptime, not counted sleeps: a sleep can run long. */
	int64_t start = k_uptime_get();

	for (;;) {
		k_sleep(K_MSEC(50));
		/* Without the board's reset OK the reset point is never reached:
		 * the window starts past any hold. */
		switch (mg_reset_hold_step(&h, mg_button_held_at_boot(),
					   (uint32_t)(k_uptime_get() - start),
					   safe_ok ? CONFIG_MG_SAFE_HOLD_MS : 0,
					   reset_ok ? CONFIG_MG_RESET_HOLD_MS : UINT32_MAX / 2,
					   CONFIG_MG_RESET_RELEASE_MS)) {
		case MG_RH_SAFE_ARM:
			mg_led_set(MG_LED_SAFE_ARMED, true);
			LOG_INF("release now for SAFE mode%s", reset_ok ? " (keep holding to reset setup)" : "");
			break;
		case MG_RH_SAFE:
			mg_led_set(MG_LED_SAFE_ARMED, false);
			return BOOT_HOLD_SAFE;
		case MG_RH_ARM:
			mg_led_set(MG_LED_SAFE_ARMED, false);
			mg_led_set(MG_LED_RESET_ARMED, true);
			LOG_INF("release now to reset setup (within %d s)",
				CONFIG_MG_RESET_RELEASE_MS / 1000);
			break;
		case MG_RH_COMMIT:
			mg_led_set(MG_LED_RESET_ARMED, false);
			return BOOT_HOLD_RESET;
		case MG_RH_CANCEL:
			mg_led_set(MG_LED_RESET_ARMED, false);
			if (!h.armed) {
				/* Released before any cue: a normal boot in setup
				 * mode, Link setup open under the normal identity
				 * (the only way a set-up XIAO takes a re-setup). */
				LOG_INF("released early: setup mode (a re-setup can be confirmed)");
				return BOOT_HOLD_SETUP;
			}
			LOG_INF("held past the release window: no reset");
			return BOOT_HOLD_NONE;
		default:
			break;
		}
	}
}

#if defined(CONFIG_MG_BENCH_MODE)
/* A bench-mode image says so in its symbols; tools/check_mic_gate.py
 * --release refuses it, so it never ships. */
__attribute__((used)) const char mg_bench_mode_image[] = "bench mode: never ships";
#endif

int main(void)
{
	bool held;

	LOG_INF("Muse Gadget %s starting (mg%d)", mg_app_version(), MG_SPEC_VERSION);
	if (strstr(mg_app_version(), ".devkey")) {
		LOG_WRN("signed with a PUBLIC development key (MCUboot's sample key): a development "
			"build, never a release");
	}
#if defined(CONFIG_MG_BENCH_MODE)
	LOG_WRN("%s: every human step scriptable", mg_bench_mode_image);
#endif
	k_work_queue_start(&app_wq, app_stack, K_THREAD_STACK_SIZEOF(app_stack),
			   K_PRIO_PREEMPT(5), NULL);
	k_thread_name_set(&app_wq.thread, "mg_app");
	/* Before any other app code: the boot count, SAFE mode, the
	 * watchdog, and the last reset's reason and breadcrumb. */
	mg_health_init();

	mg_led_init();
	held = mg_button_held_at_boot();

	bool settings_ok = settings_subsys_init() == 0;

	if (!settings_ok) {
		LOG_ERR("settings unavailable; using defaults (this boot won't count healthy)");
	}
	mg_health_persist();
	/* SAFE mode: Bluetooth, the mg service's status and SMP firmware
	 * updates only; no audio, clips, push-to-talk, Link setup or bench. */
	bool safe = mg_health_safe();
	bool setup_hold = false; /* the button held at boot, released early */

#if defined(CONFIG_MG_POWER_OFF)
	/* Plugging in turns it on: an unplug after a power off on USB, or
	 * a low cell, keeps it off or charging dark before the radio starts.
	 * Never in SAFE mode (the recovery tiers come first). */
	if (!safe) {
		mg_power_boot_gate();
	}
#endif
	/* From here a boot must become reachable within 30 s and stay
	 * reachable (after the power gate: charging dark isn't an app boot). */
	mg_health_reach_start();
	(void)mg_settings_load();
	mg_clock_load();
	(void)mg_setup_store_load();

	/* A bench-mode image's scripted SAFE / setup-reset request, taken as
	 * the boot hold would be (board hooks don't apply: the request is the
	 * bench rig's, not a hand's). A SAFE the gadget is already in by itself
	 * becomes the bench's. */
	uint8_t bench = mg_health_bench_taken();

	if (bench & MG_BOOT_F_BENCH_SAFE) {
		mg_health_set_safe_bench();
		mg_health_peer_bound_clear("SAFE asked by the bench");
		safe = true;
		held = false;
		LOG_ERR("SAFE mode (bench request): Bluetooth and firmware updates only until the "
			"next reset; recovery reason bench");
	} else if ((bench & MG_BOOT_F_BENCH_RESET) && !safe) {
		mg_health_peer_bound_clear("reset asked by the bench");
		(void)mg_setup_factory_reset("bench request (scripted setup reset hold)");
		held = false;
	}
	if (safe && held) {
		/* A SAFE the gadget entered by itself still reads the boot hold
		 * (otherwise a set-up gadget's own SAFE has no physical way out).
		 * Either release point makes it the button's SAFE, which takes
		 * Bluetooth updates; the setup reset waits for a normal boot (the
		 * clip store isn't open in SAFE). */
		enum boot_hold h = held_for_reset();

		if ((h == BOOT_HOLD_SAFE || h == BOOT_HOLD_RESET) && !mg_health_safe_by_button()) {
			mg_health_set_safe_by_button();
			mg_health_peer_bound_clear("SAFE taken over by the button");
			LOG_ERR("SAFE mode, now the button's: Bluetooth updates are open until the "
				"next reset%s", h == BOOT_HOLD_RESET ? " (reset setup from a normal boot)" : "");
		}
	} else if (held) {
		switch (held_for_reset()) {
		case BOOT_HOLD_RESET:
			mg_health_peer_bound_clear("reset asked by the button");
			(void)mg_setup_factory_reset("button held at power-up");
			break;
		case BOOT_HOLD_SAFE:
			/* This boot runs as SAFE mode; the boot record's count and the
			 * healthy mark apply as to any SAFE boot. */
			mg_health_set_safe_by_button();
			mg_health_peer_bound_clear("SAFE asked by the button");
			safe = true;
			LOG_ERR("SAFE mode (asked by the button at power-up): Bluetooth and "
				"firmware updates only until the next reset");
			break;
		case BOOT_HOLD_SETUP:
			setup_hold = true;
			break;
		default:
			break;
		}
	}
	/* Board-ready: what this boot needs up before it counts healthy. SAFE
	 * mode runs no audio or clips, so it needs the core only. */
	mg_health_ready_need(MG_READY_CORE |
			     (safe ? 0
				   : MG_READY_AUDIO | MG_READY_BOARD |
					     (IS_ENABLED(CONFIG_MG_AUDIO_QUEUE) ? MG_READY_QUEUE : 0)));
#if defined(CONFIG_MG_AUDIO_QUEUE)
	if (!safe) {
		if (mg_queue_init() == 0) {
			mg_health_ready(MG_READY_QUEUE);
		} else {
			LOG_ERR("clip store not mounted: this boot won't count healthy");
		}
	}
#endif
#if defined(CONFIG_MG_DFU)
	mg_ota_init();
#endif
	if (!safe) {
		/* An owner change's erase, owed from before, once the update's
		 * slot check has run; the queue stays closed until it ends. */
		mg_setup_clips_resume();
	}
	mg_core_init();
	if (!safe) {
		mg_audio_init();
		if (mg_audio_src_probe() == 0) {
			mg_health_ready(MG_READY_AUDIO);
		} else {
			LOG_ERR("mic source not ready: this boot won't count healthy");
		}
	}

	if (mg_ble_init()) {
		return 0;
	}
	/* After BLE: the identity comes from the address. */
	if (!safe) {
		mg_setup_init();
		if (mg_setup_mode_begins(safe, setup_hold)) {
			mg_setup_mode_begin(); /* the button held at boot */
		}
	}
	mg_session_init();
#if defined(CONFIG_MG_VM_SESSION)
	mg_vm_session_init();
	(void)mg_vm_commands_init();
#endif
	mg_core_link_refresh();
#if defined(CONFIG_MG_NUS)
	mg_nus_init();
#endif
#if defined(CONFIG_MG_BATTERY_ADC)
	mg_power_set_shutdown_mv(CONFIG_MG_BATTERY_SHUTDOWN_MV);
#endif
	k_work_init_delayable(&battery_work, battery_fn);
	k_work_reschedule(&battery_work, K_NO_WAIT);
	if (settings_ok) {
		mg_health_ready(MG_READY_CORE); /* settings, core, session and setup up */
	}
	/* Button events count from here: gpio-keys reports edges from boot, and
	 * one before the core, the session and Link setup are up is dropped
	 * (the boot hold above reads the pin itself). */
	mg_button_init();
	int err = mg_ble_start_advertising();

	if (!err) {
		/* Healthy CONFIG_MG_HEALTHY_AFTER_MS from now if the threads keep
		 * up: then the boot count starts over and a test image is kept. */
		mg_health_advertising();
	}
#if defined(CONFIG_MG_BENCH)
	if (!safe) {
		mg_bench_init();
	}
#endif
	return 0;
}
```

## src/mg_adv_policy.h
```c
/*
 * Copyright (c) Meta Platforms, Inc. and affiliates.
 *
 * Licensed under the Apache License, Version 2.0 (the "License");
 * you may not use this file except in compliance with the License.
 * You may obtain a copy of the License at
 *
 *     http://www.apache.org/licenses/LICENSE-2.0
 *
 * Unless required by applicable law or agreed to in writing, software
 * distributed under the License is distributed on an "AS IS" BASIS,
 * WITHOUT WARRANTIES OR CONDITIONS OF ANY KIND, either express or implied.
 * See the License for the specific language governing permissions and
 * limitations under the License.
 */

#ifndef MG_ADV_POLICY_H
#define MG_ADV_POLICY_H

#include <stdbool.h>
#include <stdint.h>

/*
 * Advertising interval: fast only in the 30 s
 * windows (boot, a press with no app connected, a disconnect), then slow;
 * before setup too: never fast without end (a gadget that advertised fast
 * forever while unprovisioned ran flat). slow_ms 0: always fast
 * (a build without a slow interval).
 */
static inline bool mg_adv_want_fast(uint32_t slow_ms, int64_t now_ms, int64_t fast_until_ms)
{
	return slow_ms == 0 || now_ms < fast_until_ms;
}

#endif /* MG_ADV_POLICY_H */
```

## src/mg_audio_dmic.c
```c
/*
 * Copyright (c) Meta Platforms, Inc. and affiliates.
 *
 * Licensed under the Apache License, Version 2.0 (the "License");
 * you may not use this file except in compliance with the License.
 * You may obtain a copy of the License at
 *
 *     http://www.apache.org/licenses/LICENSE-2.0
 *
 * Unless required by applicable law or agreed to in writing, software
 * distributed under the License is distributed on an "AS IS" BASIS,
 * WITHOUT WARRANTIES OR CONDITIONS OF ANY KIND, either express or implied.
 * See the License for the specific language governing permissions and
 * limitations under the License.
 */

#include <errno.h>
#include <string.h>

#include <zephyr/audio/dmic.h>
#include <zephyr/device.h>
#include <zephyr/kernel.h>
#include <zephyr/logging/log.h>

#include "mg_audio.h"
#if defined(CONFIG_MG_LC3_24K)
#include "mg_resample.h"
#endif

#if defined(CONFIG_MG_DMIC_HW_GAIN_DB) && DT_NODE_HAS_COMPAT(DT_NODELABEL(dmic_dev), nordic_nrf_pdm)
#include <hal/nrf_pdm.h>
#define HW_GAIN 1
#endif

LOG_MODULE_REGISTER(mg_dmic, CONFIG_MG_LOG_LEVEL);

/* The Sense's PDM microphone, mono 16-bit, in blocks of 160 samples: 10 ms
 * at 16 kHz. For 24 kHz (CONFIG_MG_LC3_24K) the PDM runs at 32 kHz,
 * which it makes exactly (32 MHz / 20 / ratio 50; 24 kHz has no exact
 * setting), two 5 ms blocks make 10 ms, and mg_resample.c brings them to
 * 240 samples at 24 kHz. Same slab either way: no RAM for the rate. */
#define BLOCK_BYTES (MG_AUDIO_BLOCK_SAMPLES * sizeof(int16_t))
#define BLOCKS      8

K_MEM_SLAB_DEFINE_STATIC(dmic_slab, BLOCK_BYTES, BLOCKS, 4);

static const struct device *const dmic = DEVICE_DT_GET(DT_NODELABEL(dmic_dev));
static bool running;
static int skip;
static uint16_t out_rate;
#if defined(CONFIG_MG_LC3_24K)
static struct mg_resample rs;
#endif

int mg_audio_src_probe(void)
{
	return device_is_ready(dmic) ? 0 : -ENODEV;
}

int mg_audio_src_start(uint16_t rate)
{
	uint32_t pdm_rate = rate;

	if (rate != 16000 && !(IS_ENABLED(CONFIG_MG_LC3_24K) && rate == 24000)) {
		return -ENOTSUP;
	}
	if (rate == 24000) {
		pdm_rate = 32000;
	}
	struct pcm_stream_cfg stream = {
		.pcm_rate = pdm_rate,
		.pcm_width = 16,
		.block_size = BLOCK_BYTES,
		.mem_slab = &dmic_slab,
	};
	struct dmic_cfg cfg = {
		.io = {
			.min_pdm_clk_freq = 1000000,
			.max_pdm_clk_freq = 3500000,
			.min_pdm_clk_dc = 40,
			.max_pdm_clk_dc = 60,
		},
		.streams = &stream,
		.channel = {
			.req_num_streams = 1,
			.req_num_chan = 1,
		},
	};
	int err;

	if (!device_is_ready(dmic)) {
		return -ENODEV;
	}
	cfg.channel.req_chan_map_lo = dmic_build_channel_map(0, 0, PDM_CHAN_LEFT);
	err = dmic_configure(dmic, &cfg);
	if (err) {
		LOG_ERR("dmic_configure: %d", err);
		return err;
	}
#if defined(HW_GAIN)
	/* The PDM's own gain, 0.5 dB steps around its 0 dB default; the driver
	 * leaves it at 0 dB. Set while stopped, before the start below. */
	nrf_pdm_gain_t g = NRF_PDM_GAIN_DEFAULT + 2 * CONFIG_MG_DMIC_HW_GAIN_DB;

	nrf_pdm_gain_set((NRF_PDM_Type *)DT_REG_ADDR(DT_NODELABEL(dmic_dev)), g, g);
#endif
	err = dmic_trigger(dmic, DMIC_TRIGGER_START);
	if (err) {
		LOG_ERR("dmic start: %d", err);
		return err;
	}
	running = true;
	out_rate = rate;
	/* The first 20 ms carry the mic's power-up transient. */
	skip = rate == 24000 ? 4 : 2;
#if defined(CONFIG_MG_LC3_24K)
	mg_resample_reset(&rs);
#endif
	return 0;
}

static int read_block(int16_t *pcm, int timeout_ms);

int mg_audio_src_read(int16_t *pcm, int timeout_ms)
{
#if defined(CONFIG_MG_LC3_24K)
	if (out_rate == 24000) {
		int16_t in32[2 * MG_AUDIO_BLOCK_SAMPLES]; /* 10 ms at 32 kHz */
		int err = read_block(in32, timeout_ms);

		if (err) {
			return err;
		}
		err = read_block(&in32[MG_AUDIO_BLOCK_SAMPLES], timeout_ms);
		if (err) {
			return err;
		}
		return (int)mg_resample_32_to_24(&rs, in32, ARRAY_SIZE(in32), pcm);
	}
#endif
	int err = read_block(pcm, timeout_ms);

	return err ? err : MG_AUDIO_BLOCK_SAMPLES;
}

static int read_block(int16_t *pcm, int timeout_ms)
{
	void *buf;
	uint32_t size;
	int err;

	do {
		err = dmic_read(dmic, 0, &buf, &size, timeout_ms);
		if (err) {
			return err;
		}
		if (skip > 0) {
			skip--;
			k_mem_slab_free(&dmic_slab, buf);
			continue;
		}
		break;
	} while (true);
	memcpy(pcm, buf, MIN(size, BLOCK_BYTES));
	if (size < BLOCK_BYTES) {
		memset((uint8_t *)pcm + size, 0, BLOCK_BYTES - size);
	}
	k_mem_slab_free(&dmic_slab, buf);
	return 0;
}

void mg_audio_src_stop(void)
{
	void *buf;
	uint32_t size;

	if (!running) {
		return;
	}
	(void)dmic_trigger(dmic, DMIC_TRIGGER_STOP);
	/* Give back whatever was still queued. */
	while (dmic_read(dmic, 0, &buf, &size, 0) == 0) {
		k_mem_slab_free(&dmic_slab, buf);
	}
	running = false;
}
```
